VERSION ""

NS_ :

BS_:

BU_:

VAL_TABLE_ Alternative_Fuel_Mode_Enum 2 "Secondary Fuel" 1 "Flex Fuel" 0 "Not in Use" ;

BO_ 3221225472 VECTOR__INDEPENDENT_SIG_MSG: 0 Vector__XXX
 SG_ Warning : 0|1@0+ (1,0) [0|1] "" Vector__XXX
 SG_ Coolant_Pump_After_Run : 0|1@0+ (1,0) [0|1] "" Vector__XXX
 SG_ Inlet_Camshaft_Actuator_On : 0|1@0+ (1,0) [0|1] "" Vector__XXX
 SG_ Air_Conditioner_Clutch : 0|1@0+ (1,0) [0|1] "" Vector__XXX
 SG_ Tip_Over_Switch : 0|1@0+ (1,0) [0|1] "" Vector__XXX
 SG_ Rain_Light_Switch : 0|1@0+ (1,0) [0|1] "" Vector__XXX
 SG_ Starter_Solenoid : 0|1@0+ (1,0) [0|1] "" Vector__XXX
 SG_ Intercooler_Spray_Pump : 0|1@0+ (1,0) [0|1] "" Vector__XXX
 SG_ Power_Steering_Pump : 0|1@0+ (1,0) [0|1] "" Vector__XXX
 SG_ Transmission_Pump : 0|1@0+ (1,0) [0|1] "" Vector__XXX
 SG_ Coolant_Tank_Pump : 0|1@0+ (1,0) [0|1] "" Vector__XXX
 SG_ Transmission_Coolant_Fan : 0|1@0+ (1,0) [0|1] "" Vector__XXX
 SG_ Coolant_Fan_2_On : 0|1@0+ (1,0) [0|1] "" Vector__XXX
 SG_ Coolant_Fan_1_On : 0|1@0+ (1,0) [0|1] "" Vector__XXX
 SG_ Fuel_Pump_On : 0|1@0+ (1,0) [0|1] "" Vector__XXX
 SG_ Engine_Run : 0|1@0+ (1,0) [0|1] "" Vector__XXX

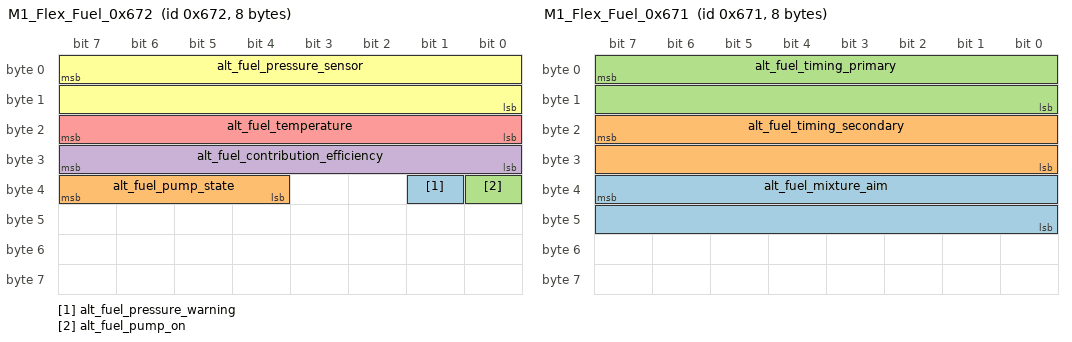
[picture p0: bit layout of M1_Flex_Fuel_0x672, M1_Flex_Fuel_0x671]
BO_ 1650 M1_Flex_Fuel_0x672: 8 Vector__XXX
 SG_ alt_fuel_pressure_warning : 33|1@0+ (1,0) [0|1] "" Vector__XXX
 SG_ alt_fuel_pump_state : 39|4@0+ (1,0) [0|15] "" Vector__XXX
 SG_ alt_fuel_pump_on : 32|1@0+ (1,0) [0|1] "" Vector__XXX
 SG_ alt_fuel_contribution_efficiency : 31|8@0+ (1,0) [0|0] "%" Vector__XXX
 SG_ alt_fuel_temperature : 23|8@0+ (1,-40) [4294967256|215] "C" Vector__XXX
 SG_ alt_fuel_pressure_sensor : 7|16@0+ (0.1,0) [0|1000] "kPa" Vector__XXX

BO_ 1649 M1_Flex_Fuel_0x671: 8 Vector__XXX
 SG_ alt_fuel_mixture_aim : 39|16@0+ (0.01,0) [0|2] "LA" Vector__XXX
 SG_ alt_fuel_timing_secondary : 23|16@0- (0.1,0) [-720|720] "deg" Vector__XXX
 SG_ alt_fuel_timing_primary : 7|16@0- (0.1,0) [-720|720] "deg" Vector__XXX

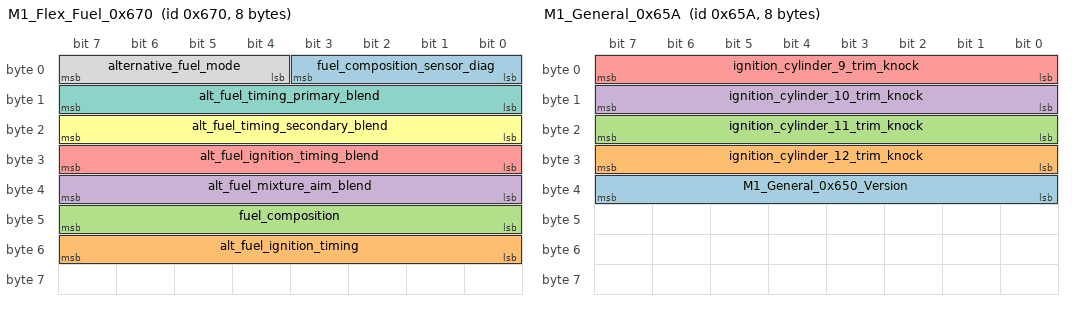
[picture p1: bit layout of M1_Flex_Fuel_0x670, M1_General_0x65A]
BO_ 1648 M1_Flex_Fuel_0x670: 8 Vector__XXX
 SG_ fuel_composition_sensor_diag : 3|4@0- (1,0) [-8|7] "" Vector__XXX
 SG_ alt_fuel_ignition_timing : 55|8@0- (0.5,0) [0|0] "deg" Vector__XXX
 SG_ fuel_composition : 47|8@0+ (1,0) [0|0] "%" Vector__XXX
 SG_ alt_fuel_mixture_aim_blend : 39|8@0+ (1,0) [0|0] "%" Vector__XXX
 SG_ alt_fuel_ignition_timing_blend : 31|8@0+ (1,0) [0|0] "%" Vector__XXX
 SG_ alt_fuel_timing_secondary_blend : 23|8@0+ (1,0) [0|0] "%" Vector__XXX
 SG_ alt_fuel_timing_primary_blend : 15|8@0+ (1,0) [0|0] "%" Vector__XXX
 SG_ alternative_fuel_mode : 7|4@0- (1,0) [0|0] "" Vector__XXX

BO_ 1626 M1_General_0x65A: 8 Vector__XXX
 SG_ M1_General_0x650_Version : 39|8@0+ (1,0) [0|0] "" Vector__XXX
 SG_ ignition_cylinder_12_trim_knock : 31|8@0+ (0.1,0) [0|25.5] "deg" Vector__XXX
 SG_ ignition_cylinder_11_trim_knock : 23|8@0+ (0.1,0) [0|25.5] "deg" Vector__XXX
 SG_ ignition_cylinder_10_trim_knock : 15|8@0+ (0.1,0) [0|25.5] "deg" Vector__XXX
 SG_ ignition_cylinder_9_trim_knock : 7|8@0+ (0.1,0) [0|25.5] "deg" Vector__XXX

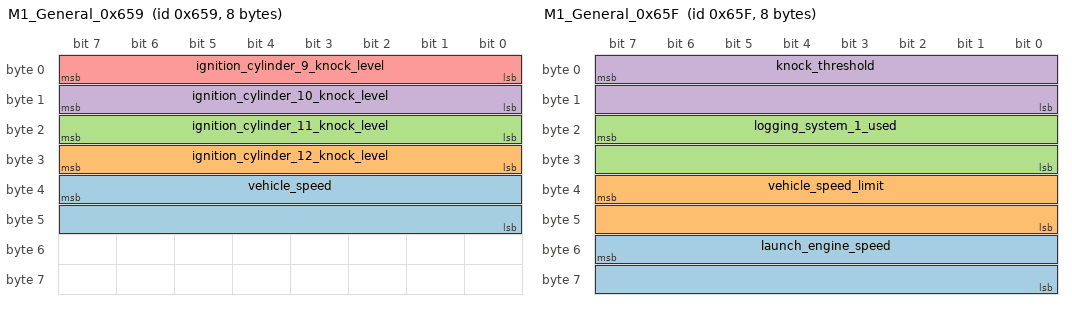
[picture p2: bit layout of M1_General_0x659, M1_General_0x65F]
BO_ 1625 M1_General_0x659: 8 Vector__XXX
 SG_ vehicle_speed : 39|16@0+ (0.1,0) [0|6553.5] "kmh" Vector__XXX
 SG_ ignition_cylinder_12_knock_level : 31|8@0+ (1,0) [0|200] "%" Vector__XXX
 SG_ ignition_cylinder_11_knock_level : 23|8@0+ (1,0) [0|200] "%" Vector__XXX
 SG_ ignition_cylinder_10_knock_level : 15|8@0+ (1,0) [0|200] "%" Vector__XXX
 SG_ ignition_cylinder_9_knock_level : 7|8@0+ (1,0) [0|200] "%" Vector__XXX

BO_ 1631 M1_General_0x65F: 8 Vector__XXX
 SG_ launch_engine_speed : 55|16@0+ (1,0) [0|16000] "RPM" Vector__XXX
 SG_ vehicle_speed_limit : 39|16@0+ (0.1,0) [0|6553.5] "kmh" Vector__XXX
 SG_ logging_system_1_used : 23|16@0+ (0.1,0) [0|0] "%" Vector__XXX
 SG_ knock_threshold : 7|16@0+ (0.1,0) [0|200] "%" Vector__XXX

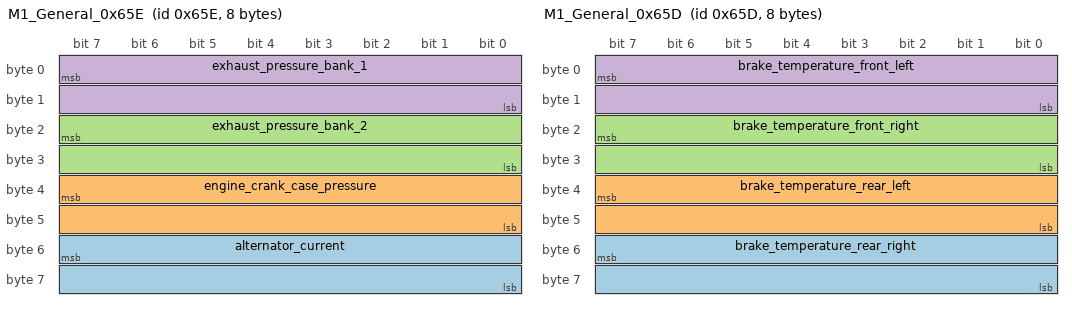
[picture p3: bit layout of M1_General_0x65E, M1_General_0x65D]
BO_ 1630 M1_General_0x65E: 8 Vector__XXX
 SG_ alternator_current : 55|16@0+ (0.01,0) [0|0] "A" Vector__XXX
 SG_ engine_crank_case_pressure : 39|16@0- (0.1,0) [0|24000] "kPa" Vector__XXX
 SG_ exhaust_pressure_bank_2 : 23|16@0- (0.1,0) [0|24000] "kPa" Vector__XXX
 SG_ exhaust_pressure_bank_1 : 7|16@0- (0.1,0) [0|24000] "kPa" Vector__XXX

BO_ 1629 M1_General_0x65D: 8 Vector__XXX
 SG_ brake_temperature_rear_right : 55|16@0- (0.1,0) [-50|1200] "C" Vector__XXX
 SG_ brake_temperature_rear_left : 39|16@0- (0.1,0) [-50|1200] "C" Vector__XXX
 SG_ brake_temperature_front_right : 23|16@0- (0.1,0) [-50|1200] "C" Vector__XXX
 SG_ brake_temperature_front_left : 7|16@0- (0.1,0) [-50|1200] "C" Vector__XXX

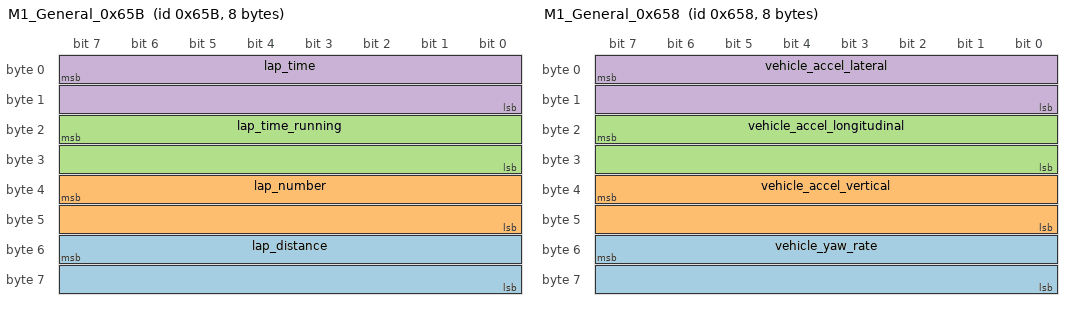
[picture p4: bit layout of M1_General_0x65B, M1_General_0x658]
BO_ 1627 M1_General_0x65B: 8 Vector__XXX
 SG_ lap_distance : 55|16@0+ (1,0) [0|0] "m" Vector__XXX
 SG_ lap_number : 39|16@0+ (1,0) [0|0] "" Vector__XXX
 SG_ lap_time_running : 23|16@0+ (0.01,0) [0|0] "s" Vector__XXX
 SG_ lap_time : 7|16@0+ (0.01,0) [0|0] "s" Vector__XXX

BO_ 1624 M1_General_0x658: 8 Vector__XXX
 SG_ vehicle_yaw_rate : 55|16@0- (0.1,0) [0|0] "deg/s" Vector__XXX
 SG_ vehicle_accel_vertical : 39|16@0- (0.001,0) [0|0] "g" Vector__XXX
 SG_ vehicle_accel_longitudinal : 23|16@0- (0.001,0) [0|0] "g" Vector__XXX
 SG_ vehicle_accel_lateral : 7|16@0- (0.001,0) [0|0] "g" Vector__XXX

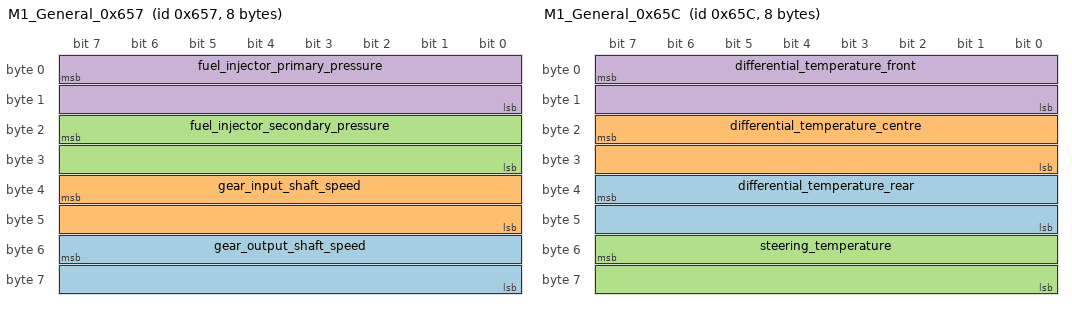
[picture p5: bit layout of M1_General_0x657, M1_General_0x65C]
BO_ 1623 M1_General_0x657: 8 Vector__XXX
 SG_ gear_output_shaft_speed : 55|16@0+ (1,0) [0|0] "RPM" Vector__XXX
 SG_ gear_input_shaft_speed : 39|16@0+ (1,0) [0|0] "RPM" Vector__XXX
 SG_ fuel_injector_secondary_pressure : 23|16@0- (0.1,0) [0|24000] "kPa" Vector__XXX
 SG_ fuel_injector_primary_pressure : 7|16@0- (0.1,0) [0|24000] "kPa" Vector__XXX

BO_ 1628 M1_General_0x65C: 8 Vector__XXX
 SG_ differential_temperature_rear : 39|16@0- (0.1,0) [-30|160] "C" Vector__XXX
 SG_ differential_temperature_centre : 23|16@0- (0.1,0) [-30|160] "C" Vector__XXX
 SG_ steering_temperature : 55|16@0- (0.1,0) [-30|160] "C" Vector__XXX
 SG_ differential_temperature_front : 7|16@0- (0.1,0) [-30|160] "C" Vector__XXX

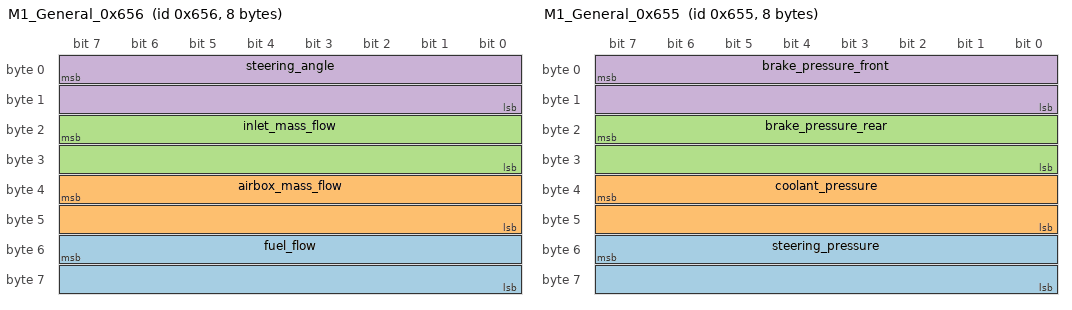
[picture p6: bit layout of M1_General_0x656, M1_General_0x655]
BO_ 1622 M1_General_0x656: 8 Vector__XXX
 SG_ fuel_flow : 55|16@0+ (0.01,0) [0|0] "ml/s" Vector__XXX
 SG_ airbox_mass_flow : 39|16@0+ (0.1,0) [0|0] "g/s" Vector__XXX
 SG_ inlet_mass_flow : 23|16@0+ (0.1,0) [0|0] "g/s" Vector__XXX
 SG_ steering_angle : 7|16@0- (0.1,0) [0|0] "" Vector__XXX

BO_ 1621 M1_General_0x655: 8 Vector__XXX
 SG_ steering_pressure : 55|16@0+ (0.1,0) [0|500] "kPa" Vector__XXX
 SG_ coolant_pressure : 39|16@0+ (0.1,0) [0|500] "kPa" Vector__XXX
 SG_ brake_pressure_rear : 23|16@0- (0.01,0) [-327.68|327.67] "bar" Vector__XXX
 SG_ brake_pressure_front : 7|16@0- (0.01,0) [-327.68|327.67] "bar" Vector__XXX

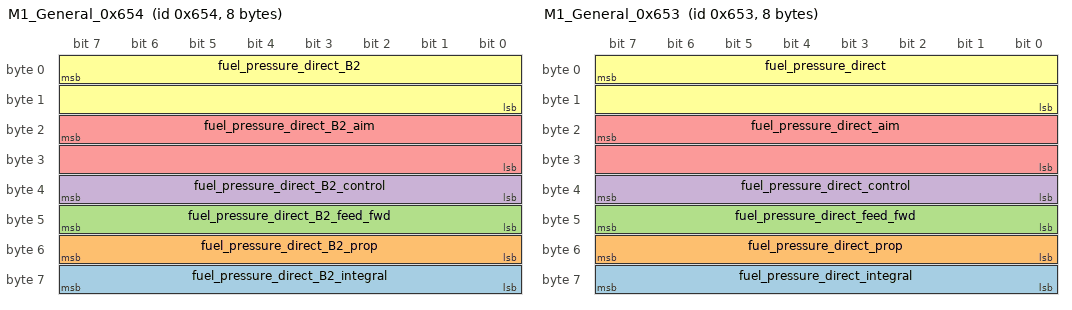
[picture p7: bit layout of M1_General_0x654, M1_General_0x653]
BO_ 1620 M1_General_0x654: 8 Vector__XXX
 SG_ fuel_pressure_direct_B2_integral : 63|8@0+ (1,0) [0|100] "%" Vector__XXX
 SG_ fuel_pressure_direct_B2_prop : 55|8@0+ (1,0) [0|100] "%" Vector__XXX
 SG_ fuel_pressure_direct_B2_feed_fwd : 47|8@0+ (1,0) [0|100] "%" Vector__XXX
 SG_ fuel_pressure_direct_B2_control : 39|8@0+ (0.5,0) [0|100] "%" Vector__XXX
 SG_ fuel_pressure_direct_B2_aim : 23|16@0+ (1,0) [0|24000] "kPa" Vector__XXX
 SG_ fuel_pressure_direct_B2 : 7|16@0+ (1,0) [0|24000] "kPa" Vector__XXX

BO_ 1619 M1_General_0x653: 8 Vector__XXX
 SG_ fuel_pressure_direct_integral : 63|8@0+ (1,0) [0|100] "%" Vector__XXX
 SG_ fuel_pressure_direct_prop : 55|8@0+ (1,0) [0|100] "%" Vector__XXX
 SG_ fuel_pressure_direct_feed_fwd : 47|8@0+ (1,0) [0|100] "%" Vector__XXX
 SG_ fuel_pressure_direct_control : 39|8@0+ (0.5,0) [0|100] "%" Vector__XXX
 SG_ fuel_pressure_direct_aim : 23|16@0+ (1,0) [0|24000] "kPa" Vector__XXX
 SG_ fuel_pressure_direct : 7|16@0+ (1,0) [0|24000] "kPa" Vector__XXX

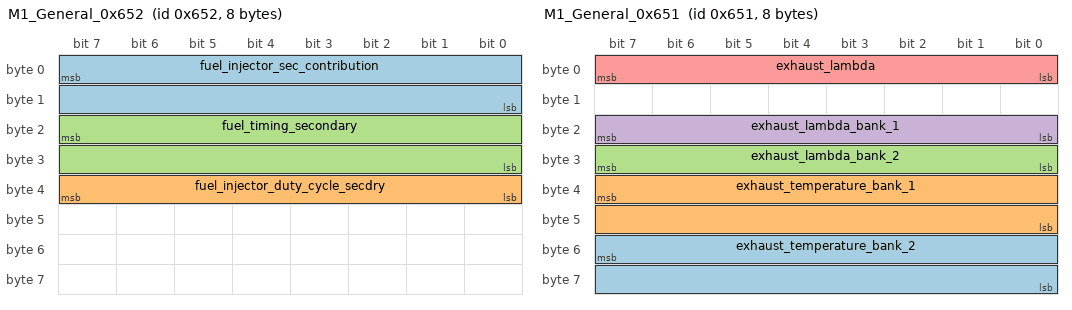
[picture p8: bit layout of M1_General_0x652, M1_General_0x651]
BO_ 1618 M1_General_0x652: 8 Vector__XXX
 SG_ fuel_injector_sec_contribution : 7|16@0+ (0.1,0) [0|100] "%" Vector__XXX
 SG_ fuel_injector_duty_cycle_secdry : 39|8@0+ (1,0) [0|100] "%" Vector__XXX
 SG_ fuel_timing_secondary : 23|16@0- (0.1,0) [-720|720] "deg" Vector__XXX

BO_ 1617 M1_General_0x651: 8 Vector__XXX
 SG_ exhaust_temperature_bank_2 : 55|16@0+ (0.1,0) [0|1200] "C" Vector__XXX
 SG_ exhaust_temperature_bank_1 : 39|16@0+ (0.1,0) [0|1200] "C" Vector__XXX
 SG_ exhaust_lambda_bank_2 : 31|8@0+ (0.01,0) [0|0] "LA" Vector__XXX
 SG_ exhaust_lambda_bank_1 : 23|8@0+ (0.01,0) [0|0] "LA" Vector__XXX
 SG_ exhaust_lambda : 7|8@0+ (0.01,0) [0|0] "LA" Vector__XXX

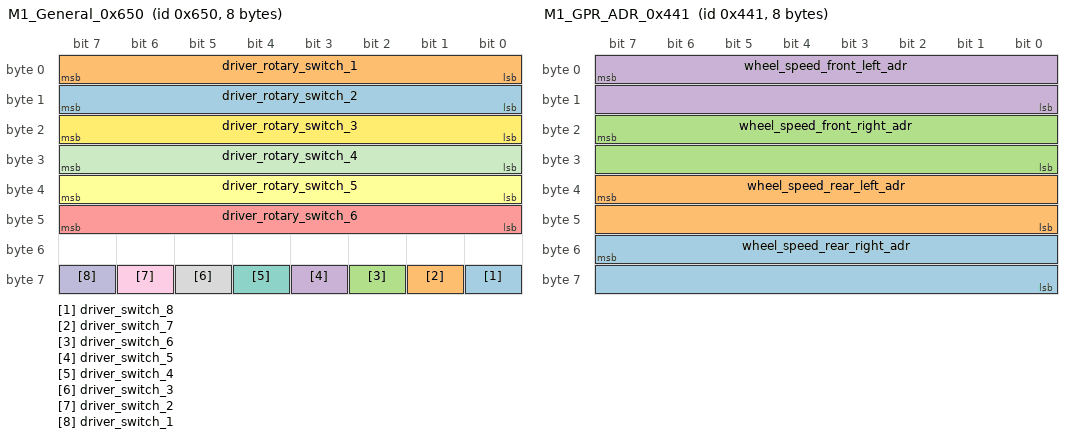
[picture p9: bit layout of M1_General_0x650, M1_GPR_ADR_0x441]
BO_ 1616 M1_General_0x650: 8 Vector__XXX
 SG_ driver_switch_8 : 56|1@0+ (1,0) [0|0] "" Vector__XXX
 SG_ driver_switch_7 : 57|1@0+ (1,0) [0|0] "" Vector__XXX
 SG_ driver_switch_6 : 58|1@0+ (1,0) [0|0] "" Vector__XXX
 SG_ driver_switch_5 : 59|1@0+ (1,0) [0|0] "" Vector__XXX
 SG_ driver_rotary_switch_6 : 47|8@0+ (1,0) [0|0] "" Vector__XXX
 SG_ driver_rotary_switch_5 : 39|8@0+ (1,0) [0|0] "" Vector__XXX
 SG_ driver_switch_4 : 60|1@0+ (1,0) [0|0] "" Vector__XXX
 SG_ driver_switch_3 : 61|1@0+ (1,0) [0|0] "" Vector__XXX
 SG_ driver_switch_2 : 62|1@0+ (1,0) [0|1] "" Vector__XXX
 SG_ driver_switch_1 : 63|1@0+ (1,0) [0|1] "" Vector__XXX
 SG_ driver_rotary_switch_4 : 31|8@0+ (1,0) [0|0] "" Vector__XXX
 SG_ driver_rotary_switch_3 : 23|8@0+ (1,0) [0|0] "" Vector__XXX
 SG_ driver_rotary_switch_2 : 15|8@0+ (1,0) [0|0] "" Vector__XXX
 SG_ driver_rotary_switch_1 : 7|8@0+ (1,0) [0|0] "" Vector__XXX

BO_ 1152 M1_LTC_Enable: 8 Vector__XXX

BO_ 1090 M1_GPR_ADR_0x442: 8 Vector__XXX
 SG_ steering_angle_adr : 7|16@0- (0.1,0) [0|0] "" Vector__XXX

BO_ 1089 M1_GPR_ADR_0x441: 8 Vector__XXX
 SG_ wheel_speed_rear_right_adr : 55|16@0+ (0.1,0) [0|340] "kmh" Vector__XXX
 SG_ wheel_speed_rear_left_adr : 39|16@0+ (0.1,0) [0|340] "kmh" Vector__XXX
 SG_ wheel_speed_front_right_adr : 23|16@0+ (0.1,0) [0|340] "kmh" Vector__XXX
 SG_ wheel_speed_front_left_adr : 7|16@0+ (0.1,0) [0|340] "kmh" Vector__XXX

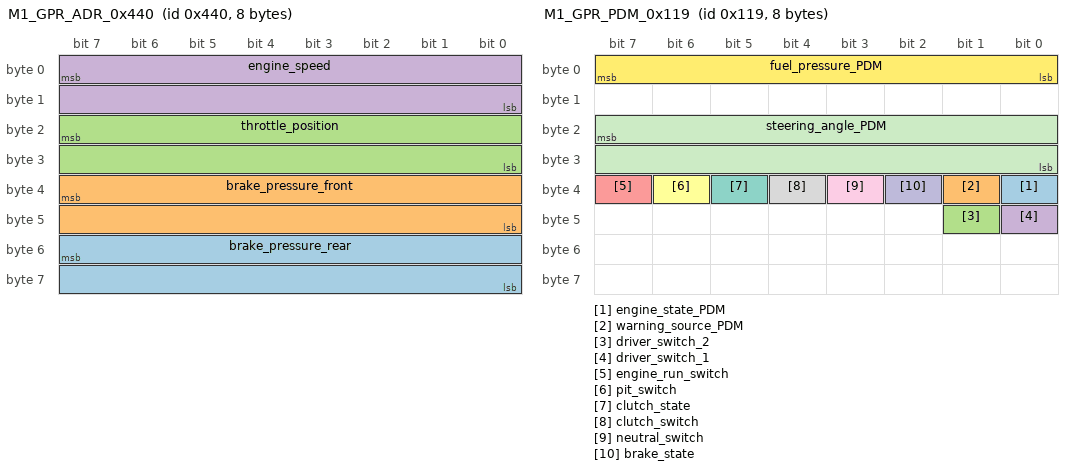
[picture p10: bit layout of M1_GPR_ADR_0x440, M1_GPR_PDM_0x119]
BO_ 1088 M1_GPR_ADR_0x440: 8 Vector__XXX
 SG_ brake_pressure_rear : 55|16@0- (0.01,0) [-327.68|327.67] "bar" Vector__XXX
 SG_ brake_pressure_front : 39|16@0- (0.01,0) [-327.68|327.67] "bar" Vector__XXX
 SG_ throttle_position : 23|16@0+ (0.1,0) [0|100] "%" Vector__XXX
 SG_ engine_speed : 7|16@0+ (6,0) [0|393210] "RPM" Vector__XXX

BO_ 282 M1_GPR_PDM_0x11A: 3 Vector__XXX
 SG_ pdm_byte_2_mask_80 : 23|1@0+ (1,0) [0|0] "" Vector__XXX
 SG_ pdm_byte_2_mask_40 : 22|1@0+ (1,0) [0|0] "" Vector__XXX
 SG_ pdm_byte_2_mask_20 : 21|1@0+ (1,0) [0|0] "" Vector__XXX
 SG_ pdm_byte_2_mask_10 : 20|1@0+ (1,0) [0|0] "" Vector__XXX
 SG_ pdm_byte_2_mask_08 : 19|1@0+ (1,0) [0|0] "" Vector__XXX
 SG_ pdm_byte_2_mask_04 : 18|1@0+ (1,0) [0|0] "" Vector__XXX
 SG_ pdm_byte_2_mask_02 : 17|1@0+ (1,0) [0|0] "" Vector__XXX
 SG_ pdm_byte_2_mask_01 : 16|1@0+ (1,0) [0|0] "" Vector__XXX
 SG_ pdm_byte_1_mask_80 : 15|1@0+ (1,0) [0|0] "" Vector__XXX
 SG_ pdm_byte_1_mask_40 : 14|1@0+ (1,0) [0|0] "" Vector__XXX
 SG_ pdm_byte_1_mask_20 : 13|1@0+ (1,0) [0|0] "" Vector__XXX
 SG_ pdm_byte_1_mask_10 : 12|1@0+ (1,0) [0|0] "" Vector__XXX
 SG_ pdm_byte_1_mask_08 : 11|1@0+ (1,0) [0|0] "" Vector__XXX
 SG_ pdm_byte_1_mask_04 : 10|1@0+ (1,0) [0|0] "" Vector__XXX
 SG_ pdm_byte_1_mask_02 : 9|1@0+ (1,0) [0|0] "" Vector__XXX
 SG_ pdm_byte_1_mask_01 : 8|1@0+ (1,0) [0|0] "" Vector__XXX
 SG_ pdm_byte_0_mask_80 : 7|1@0+ (1,0) [0|0] "" Vector__XXX
 SG_ pdm_byte_0_mask_40 : 6|1@0+ (1,0) [0|0] "" Vector__XXX
 SG_ pdm_byte_0_mask_20 : 5|1@0+ (1,0) [0|0] "" Vector__XXX
 SG_ pdm_byte_0_mask_10 : 4|1@0+ (1,0) [0|0] "" Vector__XXX
 SG_ pdm_byte_0_mask_08 : 3|1@0+ (1,0) [0|0] "" Vector__XXX
 SG_ pdm_byte_0_mask_04 : 2|1@0+ (1,0) [0|0] "" Vector__XXX
 SG_ pdm_byte_0_mask_02 : 1|1@0+ (1,0) [0|0] "" Vector__XXX
 SG_ pdm_byte_0_mask_01 : 0|1@0+ (1,0) [0|0] "" Vector__XXX

BO_ 281 M1_GPR_PDM_0x119: 8 Vector__XXX
 SG_ engine_state_PDM : 32|1@0+ (1,0) [0|1] "" Vector__XXX
 SG_ warning_source_PDM : 33|1@0+ (1,0) [0|1] "" Vector__XXX
 SG_ driver_switch_2 : 41|1@0+ (1,0) [0|1] "" Vector__XXX
 SG_ driver_switch_1 : 40|1@0+ (1,0) [0|1] "" Vector__XXX
 SG_ engine_run_switch : 39|1@0+ (1,0) [0|1] "" Vector__XXX
 SG_ pit_switch : 38|1@0+ (1,0) [0|1] "" Vector__XXX
 SG_ clutch_state : 37|1@0+ (1,0) [0|1] "" Vector__XXX
 SG_ clutch_switch : 36|1@0+ (1,0) [0|1] "" Vector__XXX
 SG_ neutral_switch : 35|1@0+ (1,0) [0|1] "" Vector__XXX
 SG_ brake_state : 34|1@0+ (1,0) [0|1] "" Vector__XXX
 SG_ steering_angle_PDM : 23|16@0- (0.1,0) [-3276|3276] "°" Vector__XXX
 SG_ fuel_pressure_PDM : 7|8@0+ (10,0) [0|2550] "kPa" Vector__XXX

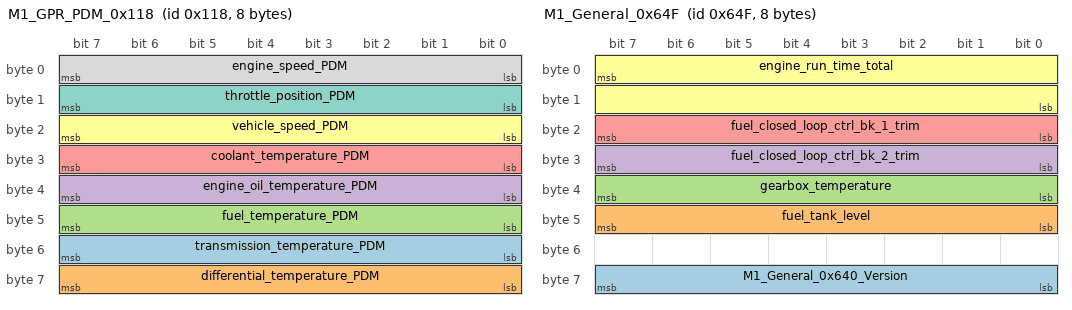
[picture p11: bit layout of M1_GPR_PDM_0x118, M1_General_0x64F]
BO_ 280 M1_GPR_PDM_0x118: 8 Vector__XXX
 SG_ transmission_temperature_PDM : 55|8@0+ (1,0) [0|255] "C" Vector__XXX
 SG_ differential_temperature_PDM : 63|8@0+ (1,0) [0|255] "C" Vector__XXX
 SG_ fuel_temperature_PDM : 47|8@0+ (1,0) [0|255] "C" Vector__XXX
 SG_ engine_oil_temperature_PDM : 39|8@0+ (1,0) [0|255] "C" Vector__XXX
 SG_ coolant_temperature_PDM : 31|8@0+ (1,0) [0|255] "C" Vector__XXX
 SG_ vehicle_speed_PDM : 23|8@0+ (1,0) [0|255] "kmh" Vector__XXX
 SG_ throttle_position_PDM : 15|8@0+ (1,0) [0|255] "%" Vector__XXX
 SG_ engine_speed_PDM : 7|8@0+ (100,0) [0|25500] "RPM" Vector__XXX

BO_ 1615 M1_General_0x64F: 8 Vector__XXX
 SG_ M1_General_0x640_Version : 63|8@0+ (1,0) [0|0] "" Vector__XXX
 SG_ fuel_tank_level : 47|8@0+ (1,0) [0|255] "l" Vector__XXX
 SG_ gearbox_temperature : 39|8@0- (1,-40) [-40|215] "C" Vector__XXX
 SG_ fuel_closed_loop_ctrl_bk_2_trim : 31|8@0+ (0.005,0) [0|1.275] "Ratio" Vector__XXX
 SG_ fuel_closed_loop_ctrl_bk_1_trim : 23|8@0+ (0.005,0) [0|1.275] "Ratio" Vector__XXX
 SG_ engine_run_time_total : 7|16@0+ (0.1,0) [0|6553.5] "hour" Vector__XXX

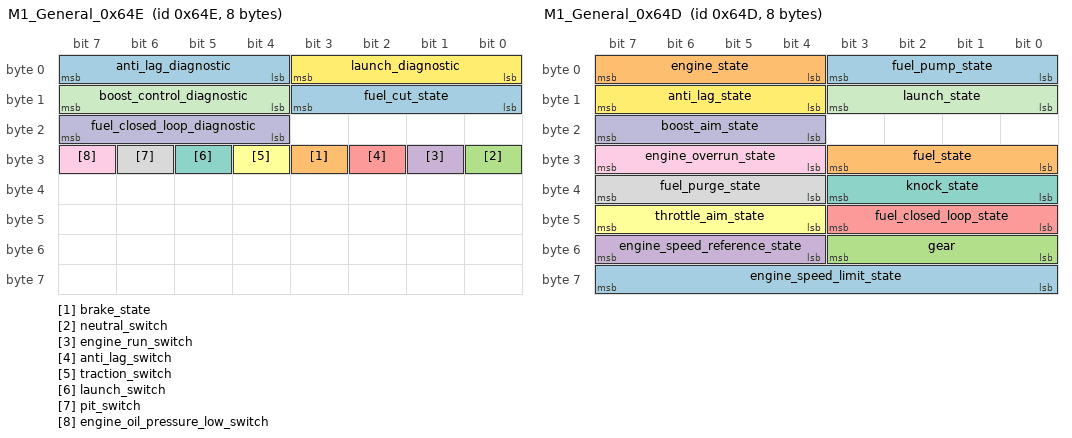
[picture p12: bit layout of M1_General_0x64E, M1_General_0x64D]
BO_ 1614 M1_General_0x64E: 8 Vector__XXX
 SG_ fuel_cut_state : 11|4@0+ (1,0) [0|15] "" Vector__XXX
 SG_ brake_state : 27|1@0+ (1,0) [0|1] "" Vector__XXX
 SG_ neutral_switch : 24|1@0+ (1,0) [0|1] "" Vector__XXX
 SG_ engine_run_switch : 25|1@0+ (1,0) [0|1] "" Vector__XXX
 SG_ anti_lag_switch : 26|1@0+ (1,0) [0|1] "" Vector__XXX
 SG_ traction_switch : 28|1@0+ (1,0) [0|1] "" Vector__XXX
 SG_ launch_switch : 29|1@0+ (1,0) [0|1] "" Vector__XXX
 SG_ pit_switch : 30|1@0+ (1,0) [0|1] "" Vector__XXX
 SG_ engine_oil_pressure_low_switch : 31|1@0+ (1,0) [0|1] "" Vector__XXX
 SG_ fuel_closed_loop_diagnostic : 23|4@0- (1,0) [-8|7] "" Vector__XXX
 SG_ boost_control_diagnostic : 15|4@0- (1,0) [-8|7] "" Vector__XXX
 SG_ launch_diagnostic : 3|4@0- (1,0) [-8|7] "" Vector__XXX
 SG_ anti_lag_diagnostic : 7|4@0- (1,0) [-8|7] "" Vector__XXX

BO_ 1613 M1_General_0x64D: 8 Vector__XXX
 SG_ engine_speed_limit_state : 63|8@0+ (1,0) [0|255] "" Vector__XXX
 SG_ fuel_state : 27|4@0+ (1,0) [0|15] "" Vector__XXX
 SG_ gear : 51|4@0- (1,0) [-8|7] "" Vector__XXX
 SG_ engine_speed_reference_state : 55|4@0+ (1,0) [0|15] "" Vector__XXX
 SG_ fuel_closed_loop_state : 43|4@0+ (1,0) [0|15] "" Vector__XXX
 SG_ throttle_aim_state : 47|4@0+ (1,0) [0|15] "" Vector__XXX
 SG_ knock_state : 35|4@0+ (1,0) [0|15] "" Vector__XXX
 SG_ fuel_purge_state : 39|4@0+ (1,0) [0|15] "" Vector__XXX
 SG_ engine_overrun_state : 31|4@0+ (1,0) [0|15] "" Vector__XXX
 SG_ boost_aim_state : 23|4@0+ (1,0) [0|15] "" Vector__XXX
 SG_ launch_state : 11|4@0+ (1,0) [0|15] "" Vector__XXX
 SG_ anti_lag_state : 15|4@0+ (1,0) [0|15] "" Vector__XXX
 SG_ fuel_pump_state : 3|4@0+ (1,0) [0|15] "" Vector__XXX
 SG_ engine_state : 7|4@0+ (1,0) [0|15] "" Vector__XXX

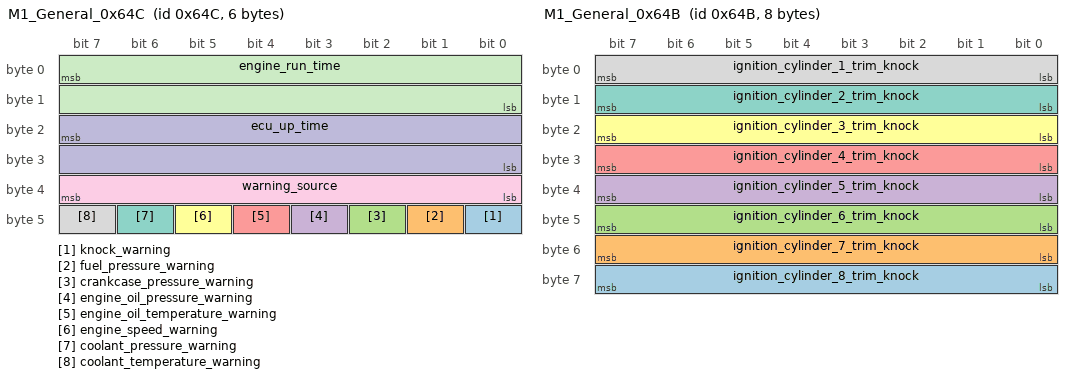
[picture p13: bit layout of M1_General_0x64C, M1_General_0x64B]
BO_ 1612 M1_General_0x64C: 6 Vector__XXX
 SG_ knock_warning : 40|1@0+ (1,0) [0|1] "" Vector__XXX
 SG_ fuel_pressure_warning : 41|1@0+ (1,0) [0|1] "" Vector__XXX
 SG_ crankcase_pressure_warning : 42|1@0+ (1,0) [0|1] "" Vector__XXX
 SG_ engine_oil_pressure_warning : 43|1@0+ (1,0) [0|1] "" Vector__XXX
 SG_ engine_oil_temperature_warning : 44|1@0+ (1,0) [0|1] "" Vector__XXX
 SG_ engine_speed_warning : 45|1@0+ (1,0) [0|1] "" Vector__XXX
 SG_ coolant_pressure_warning : 46|1@0+ (1,0) [0|1] "" Vector__XXX
 SG_ coolant_temperature_warning : 47|1@0+ (1,0) [0|1] "" Vector__XXX
 SG_ warning_source : 39|8@0+ (1,0) [0|0] "" Vector__XXX
 SG_ ecu_up_time : 23|16@0+ (1,0) [0|65535] "s" Vector__XXX
 SG_ engine_run_time : 7|16@0+ (1,0) [0|65535] "s" Vector__XXX

BO_ 1611 M1_General_0x64B: 8 Vector__XXX
 SG_ ignition_cylinder_8_trim_knock : 63|8@0+ (0.1,0) [0|25.5] "deg" Vector__XXX
 SG_ ignition_cylinder_7_trim_knock : 55|8@0+ (0.1,0) [0|25.5] "deg" Vector__XXX
 SG_ ignition_cylinder_6_trim_knock : 47|8@0+ (0.1,0) [0|25.5] "deg" Vector__XXX
 SG_ ignition_cylinder_5_trim_knock : 39|8@0+ (0.1,0) [0|25.5] "deg" Vector__XXX
 SG_ ignition_cylinder_4_trim_knock : 31|8@0+ (0.1,0) [0|25.5] "deg" Vector__XXX
 SG_ ignition_cylinder_3_trim_knock : 23|8@0+ (0.1,0) [0|25.5] "deg" Vector__XXX
 SG_ ignition_cylinder_2_trim_knock : 15|8@0+ (0.1,0) [0|25.5] "deg" Vector__XXX
 SG_ ignition_cylinder_1_trim_knock : 7|8@0+ (0.1,0) [0|25.5] "deg" Vector__XXX

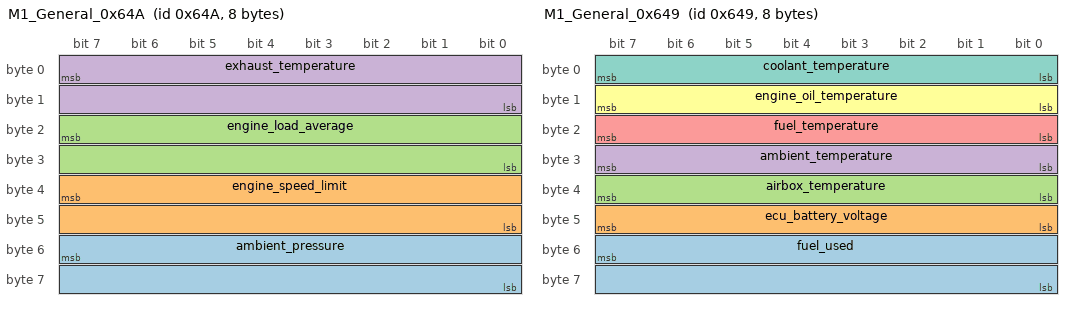
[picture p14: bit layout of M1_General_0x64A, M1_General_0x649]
BO_ 1610 M1_General_0x64A: 8 Vector__XXX
 SG_ ambient_pressure : 55|16@0- (0.1,0) [60|110] "kPa" Vector__XXX
 SG_ engine_speed_limit : 39|16@0+ (1,0) [0|16000] "RPM" Vector__XXX
 SG_ engine_load_average : 23|16@0+ (0.1,0) [0|100] "%" Vector__XXX
 SG_ exhaust_temperature : 7|16@0+ (0.1,0) [0|1200] "C" Vector__XXX

BO_ 1609 M1_General_0x649: 8 Vector__XXX
 SG_ fuel_used : 55|16@0+ (0.01,0) [0|655.35] "l" Vector__XXX
 SG_ ecu_battery_voltage : 47|8@0+ (0.1,0) [0|25.5] "V" Vector__XXX
 SG_ airbox_temperature : 39|8@0- (1,-40) [-40|215] "C" Vector__XXX
 SG_ ambient_temperature : 31|8@0- (1,-40) [-40|215] "C" Vector__XXX
 SG_ fuel_temperature : 23|8@0- (1,-40) [-40|215] "C" Vector__XXX
 SG_ engine_oil_temperature : 15|8@0- (1,-40) [-40|215] "C" Vector__XXX
 SG_ coolant_temperature : 7|8@0- (1,-40) [-40|215] "C" Vector__XXX

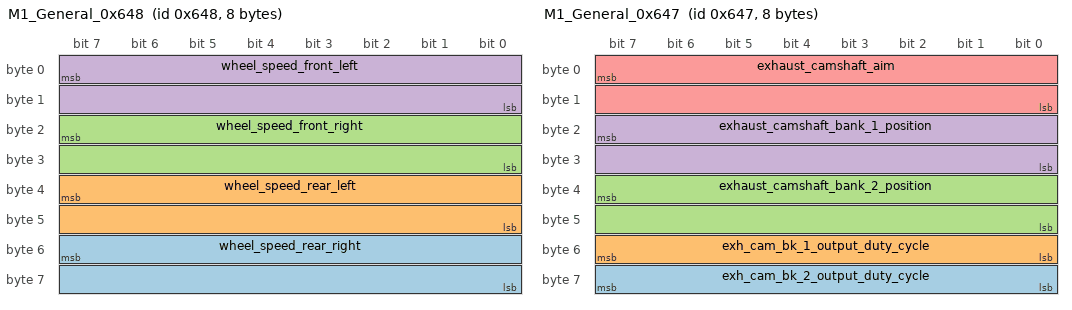
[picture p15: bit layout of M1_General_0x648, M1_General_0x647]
BO_ 1608 M1_General_0x648: 8 Vector__XXX
 SG_ wheel_speed_rear_right : 55|16@0+ (0.1,0) [0|340] "kmh" Vector__XXX
 SG_ wheel_speed_rear_left : 39|16@0+ (0.1,0) [0|340] "kmh" Vector__XXX
 SG_ wheel_speed_front_right : 23|16@0+ (0.1,0) [0|340] "kmh" Vector__XXX
 SG_ wheel_speed_front_left : 7|16@0+ (0.1,0) [0|340] "kmh" Vector__XXX

BO_ 1607 M1_General_0x647: 8 Vector__XXX
 SG_ exh_cam_bk_2_output_duty_cycle : 63|8@0+ (1,0) [0|100] "%" Vector__XXX
 SG_ exh_cam_bk_1_output_duty_cycle : 55|8@0+ (1,0) [0|100] "%" Vector__XXX
 SG_ exhaust_camshaft_bank_2_position : 39|16@0- (0.1,0) [-60|60] "deg" Vector__XXX
 SG_ exhaust_camshaft_bank_1_position : 23|16@0- (0.1,0) [-60|60] "deg" Vector__XXX
 SG_ exhaust_camshaft_aim : 7|16@0- (0.1,0) [-60|60] "deg" Vector__XXX

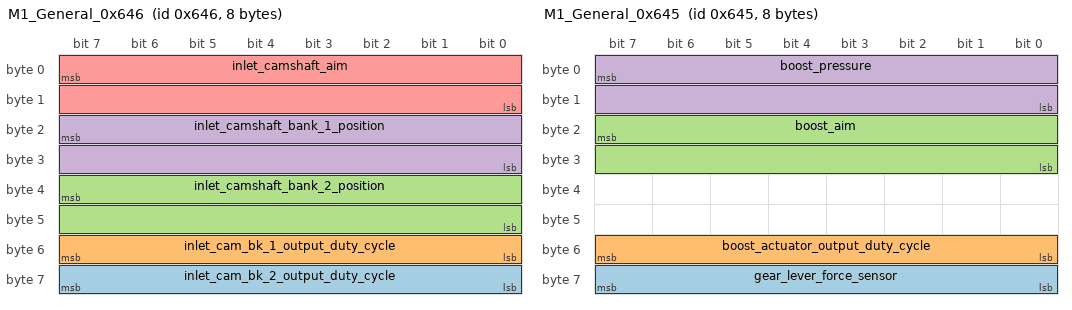
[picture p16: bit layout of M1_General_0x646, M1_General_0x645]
BO_ 1606 M1_General_0x646: 8 Vector__XXX
 SG_ inlet_cam_bk_2_output_duty_cycle : 63|8@0+ (1,0) [0|100] "%" Vector__XXX
 SG_ inlet_cam_bk_1_output_duty_cycle : 55|8@0+ (1,0) [0|100] "%" Vector__XXX
 SG_ inlet_camshaft_bank_2_position : 39|16@0- (0.1,0) [-60|60] "deg" Vector__XXX
 SG_ inlet_camshaft_bank_1_position : 23|16@0- (0.1,0) [-60|60] "deg" Vector__XXX
 SG_ inlet_camshaft_aim : 7|16@0- (0.1,0) [-60|60] "deg" Vector__XXX

BO_ 1605 M1_General_0x645: 8 Vector__XXX
 SG_ gear_lever_force_sensor : 63|8@0- (5,0) [-635|635] "N" Vector__XXX
 SG_ boost_actuator_output_duty_cycle : 55|8@0+ (1,0) [0|100] "%" Vector__XXX
 SG_ boost_aim : 23|16@0+ (0.1,0) [0|1000] "kPa" Vector__XXX
 SG_ boost_pressure : 7|16@0- (0.1,0) [0|1000] "kPa" Vector__XXX

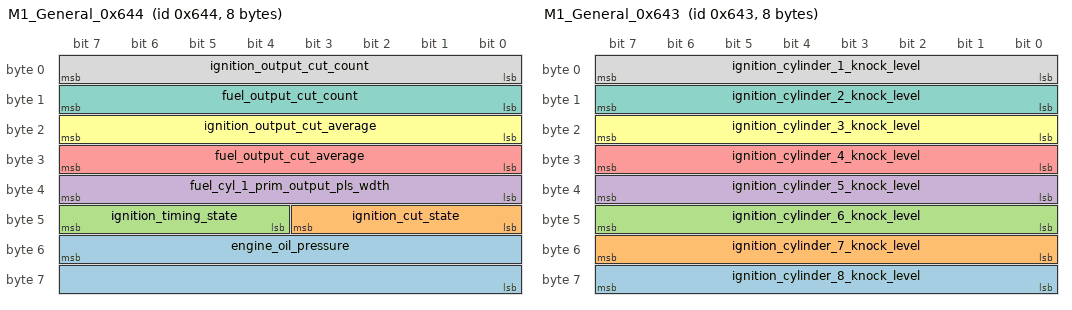
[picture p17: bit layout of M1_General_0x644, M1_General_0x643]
BO_ 1604 M1_General_0x644: 8 Vector__XXX
 SG_ engine_oil_pressure : 55|16@0+ (0.1,0) [0|0] "kPa" Vector__XXX
 SG_ ignition_cut_state : 43|4@0+ (1,0) [0|15] "Enumerated" Vector__XXX
 SG_ ignition_timing_state : 47|4@0+ (1,0) [0|15] "Enumerated" Vector__XXX
 SG_ fuel_cyl_1_prim_output_pls_wdth : 39|8@0+ (0.1,0) [0|25.5] "mS" Vector__XXX
 SG_ fuel_output_cut_average : 31|8@0+ (1,0) [0|100] "%" Vector__XXX
 SG_ ignition_output_cut_average : 23|8@0+ (1,0) [0|100] "%" Vector__XXX
 SG_ fuel_output_cut_count : 15|8@0+ (1,0) [0|255] "" Vector__XXX
 SG_ ignition_output_cut_count : 7|8@0+ (1,0) [0|255] "" Vector__XXX

BO_ 1603 M1_General_0x643: 8 Vector__XXX
 SG_ ignition_cylinder_8_knock_level : 63|8@0+ (1,0) [0|200] "%" Vector__XXX
 SG_ ignition_cylinder_7_knock_level : 55|8@0+ (1,0) [0|200] "%" Vector__XXX
 SG_ ignition_cylinder_6_knock_level : 47|8@0+ (1,0) [0|200] "%" Vector__XXX
 SG_ ignition_cylinder_5_knock_level : 39|8@0+ (1,0) [0|200] "%" Vector__XXX
 SG_ ignition_cylinder_4_knock_level : 31|8@0+ (1,0) [0|200] "%" Vector__XXX
 SG_ ignition_cylinder_3_knock_level : 23|8@0+ (1,0) [0|200] "%" Vector__XXX
 SG_ ignition_cylinder_2_knock_level : 15|8@0+ (1,0) [0|200] "%" Vector__XXX
 SG_ ignition_cylinder_1_knock_level : 7|8@0+ (1,0) [0|200] "%" Vector__XXX

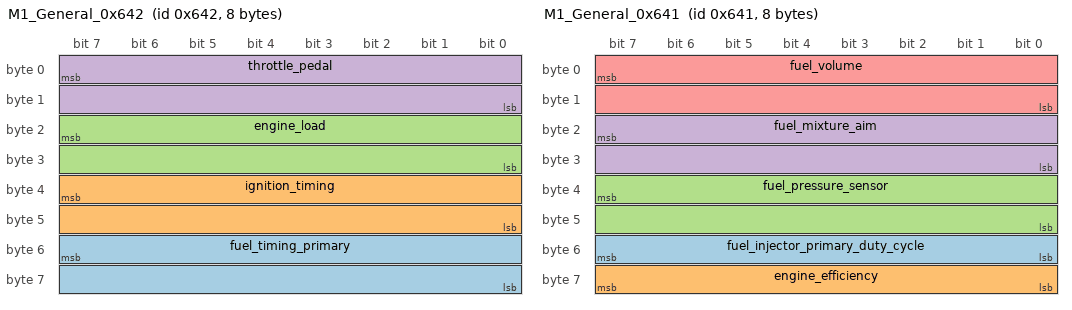
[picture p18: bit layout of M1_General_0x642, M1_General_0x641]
BO_ 1602 M1_General_0x642: 8 Vector__XXX
 SG_ fuel_timing_primary : 55|16@0- (0.1,0) [-720|720] "deg" Vector__XXX
 SG_ ignition_timing : 39|16@0- (0.1,0) [-100|100] "deg" Vector__XXX
 SG_ engine_load : 23|16@0+ (1,0) [0|1000] "mg" Vector__XXX
 SG_ throttle_pedal : 7|16@0+ (0.1,0) [0|100] "%" Vector__XXX

BO_ 1601 M1_General_0x641: 8 Vector__XXX
 SG_ fuel_injector_primary_duty_cycle : 55|8@0+ (1,0) [0|100] "%" Vector__XXX
 SG_ engine_efficiency : 63|8@0+ (1,0) [0|160] "%" Vector__XXX
 SG_ fuel_pressure_sensor : 39|16@0+ (0.1,0) [0|1000] "kPa" Vector__XXX
 SG_ fuel_mixture_aim : 23|16@0+ (0.01,0) [0|2] "LA" Vector__XXX
 SG_ fuel_volume : 7|16@0+ (1,0) [0|500] "ul" Vector__XXX

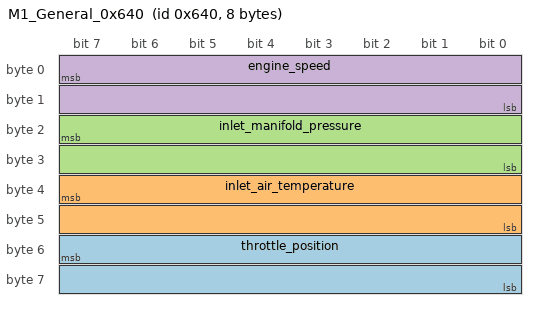
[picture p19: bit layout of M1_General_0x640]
BO_ 1600 M1_General_0x640: 8 Vector__XXX
 SG_ throttle_position : 55|16@0+ (0.1,0) [0|100] "%" Vector__XXX
 SG_ inlet_air_temperature : 39|16@0- (0.1,0) [-40|120] "C" Vector__XXX
 SG_ inlet_manifold_pressure : 23|16@0+ (0.1,0) [0|500] "kPa" Vector__XXX
 SG_ engine_speed : 7|16@0+ (1,0) [0|16000] "RPM" Vector__XXX

CM_ BO_ 3221225472 "This is a message for not used signals, created by Vector CANdb++ DBC OLE DB Provider.";
CM_ SG_ 1649 alt_fuel_timing_secondary "-ve means BTDC";
CM_ SG_ 1649 alt_fuel_timing_primary "-ve means BTDC";
CM_ SG_ 1626 ignition_cylinder_12_trim_knock "+ve means ATDC";
CM_ SG_ 1626 ignition_cylinder_11_trim_knock "+ve means ATDC";
CM_ SG_ 1626 ignition_cylinder_10_trim_knock "+ve means ATDC";
CM_ SG_ 1626 ignition_cylinder_9_trim_knock "+ve means ATDC";
CM_ SG_ 1618 fuel_timing_secondary "-ve means BTDC";
CM_ SG_ 1615 engine_run_time_total "Does not roll over";
CM_ SG_ 1612 ecu_up_time "Does not roll over";
CM_ SG_ 1612 engine_run_time "Does not roll over";
CM_ SG_ 1611 ignition_cylinder_8_trim_knock "+ve means ATDC";
CM_ SG_ 1611 ignition_cylinder_7_trim_knock "+ve means ATDC";
CM_ SG_ 1611 ignition_cylinder_6_trim_knock "+ve means ATDC";
CM_ SG_ 1611 ignition_cylinder_5_trim_knock "+ve means ATDC";
CM_ SG_ 1611 ignition_cylinder_4_trim_knock "+ve means ATDC";
CM_ SG_ 1611 ignition_cylinder_3_trim_knock "+ve means ATDC";
CM_ SG_ 1611 ignition_cylinder_2_trim_knock "+ve means ATDC";
CM_ SG_ 1611 ignition_cylinder_1_trim_knock "+ve means ATDC";
CM_ SG_ 1607 exhaust_camshaft_bank_2_position "-ve means BTDC";
CM_ SG_ 1607 exhaust_camshaft_bank_1_position "-ve means BTDC";
CM_ SG_ 1607 exhaust_camshaft_aim "-ve means BTDC";
CM_ SG_ 1606 inlet_camshaft_bank_2_position "-ve means BTDC";
CM_ SG_ 1606 inlet_camshaft_bank_1_position "-ve means BTDC";
CM_ SG_ 1606 inlet_camshaft_aim "-ve means BTDC";
CM_ SG_ 1604 fuel_output_cut_average "Rolls over at 255";
CM_ SG_ 1604 ignition_output_cut_average "Rolls over at 255
";
CM_ SG_ 1604 fuel_output_cut_count "Rolls over at 255
";
CM_ SG_ 1604 ignition_output_cut_count "Rolls over at 255
";
CM_ SG_ 1602 fuel_timing_primary "-ve means BTDC";
CM_ SG_ 1602 ignition_timing "-ve means BTDC";
VAL_ 1648 alternative_fuel_mode 2 "Secondary Fuel" 1 "Flex Fuel" 0 "Not in Use" ;
